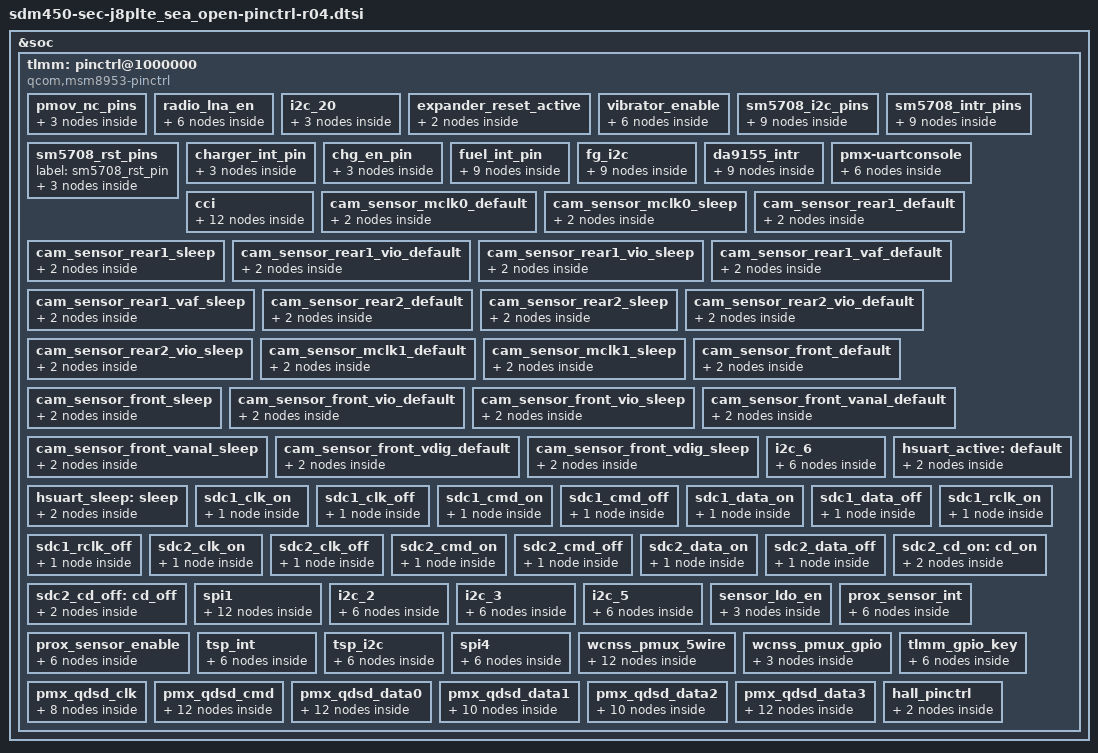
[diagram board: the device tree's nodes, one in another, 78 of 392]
/*
 * Copyright (c) 2015-2016, The Linux Foundation. All rights reserved.
 *
 * This program is free software; you can redistribute it and/or modify
 * it under the terms of the GNU General Public License version 2 and
 * only version 2 as published by the Free Software Foundation.
 *
 * This program is distributed in the hope that it will be useful,
 * but WITHOUT ANY WARRANTY; without even the implied warranty of
 * MERCHANTABILITY or FITNESS FOR A PARTICULAR PURPOSE.  See the
 * GNU General Public License for more details.
 */

#include "sdm450-sec-j8plte_audio-pinctrl.dtsi"

&soc {
	tlmm: pinctrl@1000000 {
		compatible = "qcom,msm8953-pinctrl";
		reg = <0x1000000 0x300000>;
		interrupts = <0 208 0>;
		gpio-controller;
		#gpio-cells = <2>;
		interrupt-controller;
		#interrupt-cells = <2>;

		pmov_nc_pins {
			label = "pmov_nc_pins";
			qcom,num-grp-pins = <1>;
			qcom,pin-func = <0>;
			nc_gpio_default: default {
				mux {
					pins = "gpio126";
					function ="gpio";
				};
				config {
					pins = "gpio126";
					drive-strength = <2>; /* 2mA */
					bias-pull-down;
					input-enable;
				};
			};
		};

		radio_lna_en {
				lna_en_default: lna_en_default {
					mux {
						pins = "gpio134";
						function = "gpio";
					};

					config {
						pins = "gpio134";
						drive-strength = <2>;
						bias-disable;
					};
				};
				lna_en_sleep: lna_en_sleep {
					mux {
						pins = "gpio134";
						function = "gpio";
					};

					config {
						pins = "gpio134";
						drive-strength = <2>;
						bias-disable;
					};
				};
		};

		i2c_20 {
			i2c_20_active: i2c_20_active {
				mux {
					pins = "gpio20", "gpio21";
					function = "gpio";
				};
				config {
					pins = "gpio20", "gpio21";
					drive-strength = <2>;
					bias-disable;
				};
			};
		};

		expander_reset_active: expander_reset_active {
			mux {
				pins = "gpio33";
				function = "gpio";
			};
			config {
				pins = "gpio33";
				drive-strength = <2>;   /* 16 mA */
				bias-disable;
				output-high;
			};
		};

		vibrator_enable{
			vibrator_enable_active: vibrator_enable_active {
				mux {
					pins = "gpio132";
					function = "gpio";
				};

				config {
					pins = "gpio132";
					drive-strength = <2>;
					output-high;
					bias-pull-down;
				};
			};

			vibrator_enable_suspend: vibrator_enable_suspend {
				mux {
					pins = "gpio132";
					function = "gpio";
				};

				config {
					pins = "gpio132";
					drive-strength = <2>;
					bias-disable;
					output-low;
				};
			};
		};

	/* MUIC - SM5708 */
		sm5708_i2c_pins {
			qcom,num-grp-pins = <2>;
			qcom,pin-func = <0>;
			label = "sm5708_gpio";
			sm5708_i2c_default: default {
				mux {
					pins = "gpio98", "gpio99";
					function = "gpio";
				};
				config {
					pins = "gpio98", "gpio99";
					drive-strength = <2>;
					bias-disable;
				};
			};
			sm5708_i2c_active: active {
				mux {
					pins = "gpio98", "gpio99";
					function = "gpio";
				};
				config {
					pins = "gpio98", "gpio99";
					drive-strength = <2>;
					bias-disable;
				};

			};
			sm5708_i2c_suspend: suspend {
				mux {
					pins = "gpio98", "gpio99";
					function = "gpio";
				};
				config {
					pins = "gpio98", "gpio99";
					drive-strength = <2>;
					bias-disable;
				};
			};
		};

		sm5708_intr_pins {
			qcom,pin-func = <0>;
			label = "sm5708_gpio_int";
			sm5708_interrupt_default: default {
				mux {
					pins = "gpio63";
					function = "gpio";
				};
				config {
					pins = "gpio63";
					drive-strength = <2>;
					bias-disable;
				};
			};
			sm5708_interrupt_active: active {
				mux {
					pins = "gpio63";
					function = "gpio";
				};
				config {
					pins = "gpio63";
					drive-strength = <2>;
					bias-disable;
				};
			};
			sm5708_interrupt_suspend: suspend {
				mux {
					pins = "gpio63";
					function = "gpio";
				};
				config {
					pins = "gpio63";
					drive-strength = <2>;
					bias-disable;
				};
			};
		};

		sm5708_rst_pins {
			label = "sm5708_rst_pin";
			sm5708_rst_default: default {
				mux {
					pins = "gpio61";
					function = "gpio";
				};
				config {
					pins = "gpio61";
					drive-strength = <2>;
					bias-disable;
					input-enable;
				};
			};
		};

		charger_int_pin {
			qcom,num-grp-pins = <1>;
			qcom,pin-func = <0>;
			label = "charger_int_gpio";
			charger_int_active: charger_int_active {
				mux {
					pins = "gpio60";
					function = "gpio";
				};
				config {
					pins = "gpio60";
					drive-strength = <2>;
					bias-disable;         /* No PULL */
				};
			};
		};

		chg_en_pin {
			pins = "gpio34";
			qcom,num-grp-pins = <1>;	
			qcom,pin-func = <0>;
			label = "chg_en_gpio";
			chg_en_default: chg_en_default {
				mux {
					pins = "gpio34";
					function = "gpio";
				};
				config {
					pins = "gpio34";
					drive-strength = <2>;
					bias-pull-down;
					output-high;
				};
			};
		};

		fuel_int_pin {
			qcom,num-grp-pins = <1>;
			qcom,pin-func = <0>;
			label = "fuel_int_gpio";

			fuel_int_default: fuel_int_default {
				mux {
					pins = "gpio62";
					function = "gpio";
				};
				config {
					pins = "gpio62";
					drive-strength = <2>;
					bias-disable;
				};
			};
			fuel_int_active: fuel_int_active {
				mux {
					pins = "gpio62";
					function = "gpio";
				};
				config {
					pins = "gpio62";
					drive-strength = <2>;
					bias-disable;
				};
			};
			fuel_int_suspend: fuel_int_suspend {
				mux {
					pins = "gpio62";
					function = "gpio";
				};
				config {
					pins = "gpio62";
					drive-strength = <2>;
					bias-disable;
				};
			};			
		};

		fg_i2c {
			qcom,num-grp-pins = <2>;
			qcom,pin-func = <0>;
			label = "sm5708_fg_gpio";
			
			fg_i2c_default: fg_i2c_default {
				mux {
					pins = "gpio38", "gpio39";
					function = "gpio";
				};
				config {
					pins = "gpio38", "gpio39";
					drive-strength = <2>;
					bias-disable; /* No PULL */
				};
			};
			fg_i2c_active: fg_i2c_active {
				mux {
					pins = "gpio38", "gpio39";
					function = "gpio";
				};
				config {
					pins = "gpio38", "gpio39";
					drive-strength = <2>;
					bias-disable; /* No PULL */
				};
			};
			fg_i2c_suspend: fg_i2c_suspend {
				mux {
					pins = "gpio38", "gpio39";
					function = "gpio";
				};
				config {
					pins = "gpio38", "gpio39";
					drive-strength = <2>;
					bias-disable; /* No PULL */
				};
			};
		};

		da9155_intr {
			qcom,pin-func = <0>;
			label = "da9155_intr";
			da9155_intr_default: default {
				mux {
					pins = "gpio9";
					function = "gpio";
				};
				config {
					pins = "gpio9";
					drive-strength = <2>;
					bias-disable;
				};
			};
			da9155_intr_active: active {
				mux {
					pins = "gpio9";
					function = "gpio";
				};
				config {
					pins = "gpio9";
					drive-strength = <2>;
					bias-disable;
				};
			};
			da9155_intr_suspend: suspend {
				mux {
					pins = "gpio9";
					function = "gpio";
				};
				config {
					pins = "gpio9";
					drive-strength = <2>;
					bias-disable;
				};
			};
		};

		pmx-uartconsole {
			uart_console_active: uart_console_active {
				mux {
					pins = "gpio4", "gpio5";
					function = "blsp_uart2";
				};

				config {
					pins = "gpio4", "gpio5";
					drive-strength = <2>;
					bias-pull-down;
				};
			};

			uart_console_sleep: uart_console_sleep {
				mux {
					pins = "gpio4", "gpio5";
					function = "blsp_uart2";
				};

				config {
					pins = "gpio4", "gpio5";
					drive-strength = <2>;
					bias-pull-down;
				};
			};

		};
		cci {
			cci0_active: cci0_active {
				/* cci0 active state */
				mux {
					/* CLK, DATA */
					pins = "gpio29", "gpio30";
					function = "cci_i2c";
				};

				config {
					pins = "gpio29", "gpio30";
					drive-strength = <2>; /* 2 MA */
					bias-disable; /* No PULL */
				};
			};

			cci0_suspend: cci0_suspend {
				/* cci0 suspended state */
				mux {
					/* CLK, DATA */
					pins = "gpio29", "gpio30";
					function = "gpio";
				};

				config {
					pins = "gpio29", "gpio30";
					drive-strength = <2>; /* 2 MA */
					bias-disable; /* No PULL */
				};
			};

			cci1_active: cci1_active {
				/* cci1 active state */
				mux {
					/* CLK, DATA */
					pins = "gpio31", "gpio32";
					function = "cci_i2c";
				};

				config {
					pins = "gpio31", "gpio32";
					drive-strength = <2>; /* 2 MA */
					bias-disable; /* No PULL */
				};
			};

			cci1_suspend: cci1_suspend {
				/* cci1 suspended state */
				mux {
					/* CLK, DATA */
					pins = "gpio31", "gpio32";
					function = "gpio";
				};

				config {
					pins = "gpio31", "gpio32";
					drive-strength = <2>; /* 2 MA */
					bias-disable; /* No PULL */
				};
			};
		};

		/*sensors */
		cam_sensor_mclk0_default: cam_sensor_mclk0_default {
			/* MCLK0 */
			mux {
				/* CLK, DATA */
				pins = "gpio26";
				function = "cam_mclk";
			};

			config {
				pins = "gpio26";
				bias-disable; /* No PULL */
				drive-strength = <4>; /* 4 MA */
			};
		};

		cam_sensor_mclk0_sleep: cam_sensor_mclk0_sleep {
			/* MCLK0 */
			mux {
				/* CLK, DATA */
				pins = "gpio26";
				function = "gpio";
			};

			config {
				pins = "gpio26";
				bias-pull-down; /* PULL DOWN */
				drive-strength = <4>; /* 4 MA */
				output-low;
			};
		};

		cam_sensor_rear1_default: cam_sensor_rear1_default {
			/* REAR MAIN RESET */
			mux {
				pins = "gpio40";
				function = "gpio";
			};

			config {
				pins = "gpio40";
				bias-pull-down; /* PULL DOWN */
				drive-strength = <2>; /* 2 MA */
				output-low;
			};
		};

		cam_sensor_rear1_sleep: cam_sensor_rear1_sleep {
			/* REAR MAIN RESET */
			mux {
				pins = "gpio40";
				function = "gpio";
			};

			config {
				pins = "gpio40";
				bias-pull-down; /* PULL DOWN */
				drive-strength = <2>; /* 2 MA */
			};
		};

		cam_sensor_rear1_vio_default: cam_sensor_rear1_vio_default {
			/* REAR MAIN VIO */
			mux {
				pins = "gpio92";
				function = "gpio";
			};

			config {
				pins = "gpio92";
				bias-pull-down; /* PULL DOWN */
				drive-strength = <2>; /* 2 MA */
				output-low;
			};
		};

		cam_sensor_rear1_vio_sleep: cam_sensor_rear1_vio_sleep {
			/* REAR MAIN VDIO */
			mux {
				pins = "gpio92";
				function = "gpio";
			};

			config {
				pins = "gpio92";
				bias-pull-down; /* PULL DOWN */
				drive-strength = <2>; /* 2 MA */
				output-low;
			};
		};

		cam_sensor_rear1_vaf_default: cam_sensor_rear1_vaf_default {
			/* REAR MAIN VAF */
			mux {
				pins = "gpio89";
				function = "gpio";
			};

			config {
				pins = "gpio89";
				bias-pull-down; /* PULL DOWN */
				drive-strength = <2>; /* 2 MA */
				output-low;
			};
		};

		cam_sensor_rear1_vaf_sleep: cam_sensor_rear1_vaf_sleep {
			/* REAR MAIN VAF */
			mux {
				pins = "gpio89";
				function = "gpio";
			};

			config {
				pins = "gpio89";
				bias-pull-down; /* PULL DOWN */
				drive-strength = <2>; /* 2 MA */
				output-low;
			};
		};

		cam_sensor_rear2_default: cam_sensor_rear2_default {
			/* REAR SUB RESET */
			mux {
				pins = "gpio41";
				function = "gpio";
			};

			config {
				pins = "gpio41";
				bias-pull-down; /* PULL DOWN */
				drive-strength = <2>; /* 2 MA */
				output-low;
			};
		};

		cam_sensor_rear2_sleep: cam_sensor_rear2_sleep {
			/* REAR SUB RESET */
			mux {
				pins = "gpio41";
				function = "gpio";
			};

			config {
				pins = "gpio41";
				bias-pull-down; /* PULL DOWN */
				drive-strength = <2>; /* 2 MA */
			};
		};

		cam_sensor_rear2_vio_default: cam_sensor_rear2_vio_default {
			/* REAR SUB VIO */
			mux {
				pins = "gpio94";
				function = "gpio";
			};

			config {
				pins = "gpio94";
				bias-pull-down; /* PULL DOWN */
				drive-strength = <2>; /* 2 MA */
				output-low;
			};
		};

		cam_sensor_rear2_vio_sleep: cam_sensor_rear2_vio_sleep {
			/* REAR SUB VIO */
			mux {
				pins = "gpio94";
				function = "gpio";
			};

			config {
				pins = "gpio94";
				bias-pull-down; /* PULL DOWN */
				drive-strength = <2>; /* 2 MA */
				output-low;
			};
		};

		cam_sensor_mclk1_default: cam_sensor_mclk1_default {
			/* MCLK1 */
			mux {
				/* CLK, DATA */
				pins = "gpio27";
				function = "cam_mclk";
			};

			config {
				pins = "gpio27";
				bias-disable; /* No PULL */
				drive-strength = <4>; /* 4 MA */
			};
		};

		cam_sensor_mclk1_sleep: cam_sensor_mclk1_sleep {
			/* MCLK1 */
			mux {
				/* CLK, DATA */
				pins = "gpio27";
				function = "gpio";
			};

			config {
				pins = "gpio27";
				bias-pull-down; /* PULL DOWN */
				drive-strength = <4>; /* 4 MA */
				output-low;
			};
		};

		cam_sensor_front_default: cam_sensor_front_default {
			/* FRONT RESET*/
			mux {
				pins = "gpio129";
				function = "gpio";
			};

			config {
				pins = "gpio129";
				bias-pull-down; /* PULL DOWN */
				output-low;
				drive-strength = <2>; /* 2 MA */
			};
		};

		cam_sensor_front_sleep: cam_sensor_front_sleep {
			/* FRONT RESET */
			mux {
				pins = "gpio129";
				function = "gpio";
			};

			config {
				pins = "gpio129";
				bias-disable; /* No PULL */
				output-low;
				drive-strength = <2>; /* 2 MA */
			};
		};

		cam_sensor_front_vio_default: cam_sensor_front_vio_default {
			/* FRONT VIO */
			mux {
				pins = "gpio90";
				function = "gpio";
			};

			config {
				pins = "gpio90";
				bias-pull-down; /* PULL DOWN */
				drive-strength = <2>; /* 2 MA */
				output-low;
			};
		};

		cam_sensor_front_vio_sleep: cam_sensor_front_vio_sleep {
			/* FRONT VIO */
			mux {
				pins = "gpio90";
				function = "gpio";
			};

			config {
				pins = "gpio90";
				bias-pull-down; /* PULL DOWN */
				drive-strength = <2>; /* 2 MA */
				output-low;
			};
		};

		cam_sensor_front_vanal_default: cam_sensor_front_vanal_default {
			/* FRONT VANAL */
			mux {
				pins = "gpio91";
				function = "gpio";
			};

			config {
				pins = "gpio91";
				bias-pull-down; /* PULL DOWN */
				drive-strength = <2>; /* 2 MA */
				output-low;
			};
		};

		cam_sensor_front_vanal_sleep: cam_sensor_front_vanal_sleep {
			/* FRONT VANAL */
			mux {
				pins = "gpio91";
				function = "gpio";
			};

			config {
				pins = "gpio91";
				bias-pull-down; /* PULL DOWN */
				drive-strength = <2>; /* 2 MA */
				output-low;
			};
		};

		cam_sensor_front_vdig_default: cam_sensor_front_vdig_default {
			/* FRONT VDIG */
			mux {
				pins = "gpio140";
				function = "gpio";
			};

			config {
				pins = "gpio140";
				bias-pull-down; /* PULL DOWN */
				drive-strength = <2>; /* 2 MA */
				output-low;
			};
		};

		cam_sensor_front_vdig_sleep: cam_sensor_front_vdig_sleep {
			/* FRONT VDIG */
			mux {
				pins = "gpio140";
				function = "gpio";
			};

			config {
				pins = "gpio140";
				bias-pull-down; /* PULL DOWN */
				drive-strength = <2>; /* 2 MA */
				output-low;
			};
		};
/*
		pmx_adv7533_int: pmx_adv7533_int {
			adv7533_int_active: adv7533_int_active {
				mux {
					pins = "gpio90";
					function = "gpio";
				};

				config {
					pins = "gpio90";
					drive-strength = <16>;
					bias-disable;
				};
			};

			adv7533_int_suspend: adv7533_int_suspend {
				mux {
					pins = "gpio90";
					function = "gpio";
				};

				config {
					pins = "gpio90";
					drive-strength = <16>;
					bias-disable;
				};
			};

		};
*/
		i2c_6 {
			i2c_6_active: i2c_6_active {
				/* active state */
				mux {
					pins = "gpio22", "gpio23";
					function = "blsp_i2c6";
				};
				config {
					pins = "gpio22", "gpio23";
					drive-strength = <2>;
					bias-disable;
				};
			};

			i2c_6_sleep: i2c_6_sleep {
				/* suspended state */
				mux {
					pins = "gpio22", "gpio23";
					function = "blsp_i2c6";
				};

				config {
					pins = "gpio22", "gpio23";
					drive-strength = <2>;
					bias-disable;
				};
			};
		};

		hsuart_active: default {
			mux {
				pins = "gpio12", "gpio13", "gpio14", "gpio15";
				function = "blsp_uart4";
			};

			config {
				pins = "gpio12", "gpio13", "gpio14", "gpio15";
				drive-strength = <16>;
				bias-disable;
			};
		};

		hsuart_sleep: sleep {
			mux {
				pins = "gpio12", "gpio13", "gpio14", "gpio15";
				function = "gpio";
			};

			config {
				pins = "gpio12", "gpio13", "gpio14", "gpio15";
				drive-strength = <2>;
				bias-disable;
			};
		};

		/* SDC pin type */
		sdc1_clk_on: sdc1_clk_on {
			config {
				pins = "sdc1_clk";
				bias-disable;		/* NO pull */
				drive-strength = <16>;	/* 16 MA */
			};
		};

		sdc1_clk_off: sdc1_clk_off {
			config {
				pins = "sdc1_clk";
				bias-disable;		/* NO pull */
				drive-strength = <2>;	/* 2 MA */
			};
		};

		sdc1_cmd_on: sdc1_cmd_on {
			config {
				pins = "sdc1_cmd";
				bias-disable;		/* NO pull */
				drive-strength = <10>;	/* 10 MA */
			};
		};

		sdc1_cmd_off: sdc1_cmd_off {
			config {
				pins = "sdc1_cmd";
				num-grp-pins = <1>;
				bias-disable;		/* NO pull */
				drive-strength = <2>;	/* 2 MA */
			};
		};

		sdc1_data_on: sdc1_data_on {
			config {
				pins = "sdc1_data";
				bias-pull-up;		/* pull up */
				drive-strength = <10>;	/* 10 MA */
			};
		};

		sdc1_data_off: sdc1_data_off {
			config {
				pins = "sdc1_data";
				bias-pull-up;		/* pull up */
				drive-strength = <2>;	/* 2 MA */
			};
		};

		sdc1_rclk_on: sdc1_rclk_on {
			config {
				pins = "sdc1_rclk";
				bias-pull-down; /* pull down */
			};
		};

		sdc1_rclk_off: sdc1_rclk_off {
			config {
				pins = "sdc1_rclk";
				bias-pull-down; /* pull down */
			};
		};

		sdc2_clk_on: sdc2_clk_on {
			config {
				pins = "sdc2_clk";
				drive-strength = <16>; /* 16 MA */
				bias-disable; /* NO pull */
			};
		};

		sdc2_clk_off: sdc2_clk_off {
			config {
				pins = "sdc2_clk";
				bias-disable; /* NO pull */
				drive-strength = <2>; /* 2 MA */
			};
		};

		sdc2_cmd_on: sdc2_cmd_on {
			config {
				pins = "sdc2_cmd";
				bias-pull-up; /* pull up */
				drive-strength = <8>; /* 8 MA */
			};
		};

		sdc2_cmd_off: sdc2_cmd_off {
			config {
				pins = "sdc2_cmd";
				bias-pull-up; /* pull up */
				drive-strength = <2>; /* 2 MA */
			};
		};

		sdc2_data_on: sdc2_data_on {
			config {
				pins = "sdc2_data";
				bias-pull-up; /* pull up */
				drive-strength = <8>; /* 8 MA */
			};
		};

		sdc2_data_off: sdc2_data_off {
			config {
				pins = "sdc2_data";
				bias-pull-up; /* pull up */
				drive-strength = <2>; /* 2 MA */
			};
		};

		sdc2_cd_on: cd_on {
			mux {
				pins = "gpio133";
				function = "gpio";
			};

			config {
				pins = "gpio133";
				drive-strength = <2>;
				bias-disable;
			};
		};

		sdc2_cd_off: cd_off {
			mux {
				pins = "gpio133";
				function = "gpio";
			};

			config {
				pins = "gpio133";
				drive-strength = <2>;
				bias-disable;
			};
		};

		spi1 {
			spi1_default: spi1_default {
				/* active state */
				mux {
					/* MOSI, MISO, CLK */
					pins = "gpio0", "gpio1", "gpio3";
					function = "blsp_spi1";
				};

				config {
					pins = "gpio0", "gpio1", "gpio2";
					drive-strength = <12>; /* 12 MA */
					bias-disable = <0>; /* No PULL */
				};
			};

			spi1_sleep: spi1_sleep {
				/* suspended state */
				mux {
					/* MOSI, MISO, CLK */
					pins = "gpio0", "gpio1", "gpio3";
					function = "gpio";
				};

				config {
					pins = "gpio0", "gpio1", "gpio3";
					drive-strength = <2>; /* 2 MA */
					bias-pull-down; /* PULL Down */
				};
			};

			spi1_cs0_active: cs0_active {
				/* CS */
				mux {
					pins = "gpio2";
					function = "blsp_spi1";
				};

				config {
					pins = "gpio2";
					drive-strength = <2>;
					bias-disable = <0>;
				};
			};

			spi1_cs0_sleep: cs0_sleep {
				/* CS */
				mux {
					pins = "gpio2";
					function = "gpio";
				};

				config {
					pins = "gpio2";
					drive-strength = <2>;
					bias-disable = <0>;
				};
			};
		};

		i2c_2 {
			i2c_2_active: i2c_2_active {
				/* active state */
				mux {
					pins = "gpio6", "gpio7";
					function = "blsp_i2c2";
				};

				config {
					pins = "gpio6", "gpio7";
					drive-strength = <2>;
					bias-disable;
				};
			};

			i2c_2_sleep: i2c_2_sleep {
				/* suspended state */
				mux {
					pins = "gpio6", "gpio7";
					function = "blsp_i2c2";
				};

				config {
					pins = "gpio6", "gpio7";
					drive-strength = <2>;
					bias-disable;
				};
			};
		};

		i2c_3 {
			i2c_3_active: i2c_3_active {
				/* active state */
				mux {
					pins = "gpio10", "gpio11";
					function = "blsp_i2c3";
				};

				config {
					pins = "gpio10", "gpio11";
					drive-strength = <2>;
					bias-disable;
				};
			};

			i2c_3_sleep: i2c_3_sleep {
				/* suspended state */
				mux {
					pins = "gpio10", "gpio11";
					function = "gpio";
				};

				config {
					pins = "gpio10", "gpio11";
					drive-strength = <2>;
					bias-disable;
				};
			};
		};

		i2c_5 {
			i2c_5_active: i2c_5_active {
				/* active state */
				mux {
					pins = "gpio18", "gpio19";
					function = "blsp_i2c5";
				};

				config {
					pins = "gpio18", "gpio19";
					drive-strength = <2>;
					bias-disable;
				};
			};

			i2c_5_sleep: i2c_5_sleep {
				/* suspended state */
				mux {
					pins = "gpio18", "gpio19";
					function = "blsp_i2c5";
				};

				config {
					pins = "gpio18", "gpio19";
					drive-strength = <2>;
					bias-disable;
				};
			};
		};

		sensor_ldo_en {
			pins = "gpio66";
			qcom,pin-func = <0>;
			qcom,num-grp-pins = <1>;
			label = "sensor_ldo_en";
			sensor_ldo_en_default: sensor_ldo_en_default {
				mux {
					pins = "gpio66";
					function = "gpio";
				};
				config {
					pins = "gpio66";
					drive-strength = <2>;
					bias-disable;
					output-high;
				};
			};
		};

		/* add pingrp for proximity sensors  */
		prox_sensor_int {
			pins = "gpio43";
			qcom,pin-func = <0>;
			qcom,num-grp-pins = <1>;
			label = "prox_sensor_int";
			prox_sensor_int_active: prox_sensor_int_active {
				mux {
					pins = "gpio43";
					function = "gpio";
				};
				config {
					pins = "gpio43";
					drive-strength = <2>;
					bias-disable;
				};
			};
			prox_sensor_int_suspend: prox_sensor_int_suspend {
				mux {
					pins = "gpio43";
					function = "gpio";
				};
				config {
					pins = "gpio43";
					drive-strength = <2>;
					bias-disable;
				};
			};
		};

		prox_sensor_enable {
			pins = "gpio96";
			qcom,pin-func = <0>;
			qcom,num-grp-pins = <1>;
			label = "prox_sensor_enable";
			prox_sensor_enable_active: prox_sensor_enable_active {
				mux {
					pins = "gpio96";
					function = "gpio";
				};
				config {
					pins = "gpio96";
					drive-strength = <2>;
					bias-pull-down;
				};
			};
			prox_sensor_enable_suspend: prox_sensor_enable_suspend {
				mux {
					pins = "gpio96";
					function = "gpio";
				};
				config {
					pins = "gpio96";
					drive-strength = <2>;
					bias-pull-down;
				};
			};
		};

		tsp_int {
			/*qcom,pins = <&gp 59>;*/ /* INTERRUPT */
			pins = "gpio59";
			qcom,num-grp-pins = <1>;
			qcom,pin-func = <0>;
			label = "tsp_int";
			tsp_int_active: tsp_int_active {
				mux {
					pins = "gpio59";
					function = "gpio";
				};
				config {
					pins = "gpio59";
					drive-strength = <2>;
					bias-disable;
				};
			};
			tsp_int_suspend: tsp_int_suspend {
				mux {
					pins = "gpio59";
					function = "gpio";
				};
				config {
					pins = "gpio59";
					drive-strength = <2>;
					bias-disable;
				};
			};
		};

		tsp_i2c {
			/*qcom,pins = <&gp 16>, <&gp 17>;*/ /* SDA, SCL */
			pins = "gpio16", "gpio17";
			qcom,num-grp-pins = <2>;
			qcom,pin-func = <0>;
			label = "tsp_i2c";
			tsp_i2c_active: tsp_i2c_active {
				mux {
					pins = "gpio16", "gpio17";
					function = "gpio";
				};
				config {
					pins = "gpio16", "gpio17";
					drive-strength = <2>;
					bias-disable;
				};
			};
			tsp_i2c_suspend: tsp_i2c_suspend {
				mux {
					pins = "gpio16", "gpio17";
					function = "gpio";
				};
				config {
					pins = "gpio16", "gpio17";
					drive-strength = <2>;
					bias-pull-down;
				};
			};
		};

		spi4 {
			spi_4_active: spi_4_active {
				mux {
					pins = "gpio12", "gpio13", "gpio14", "gpio15";
					function = "blsp_spi4";
				};

				config {
					pins = "gpio12", "gpio13", "gpio14", "gpio15";
					drive-strength = <2>;
					bias-pull-up;
				};
			};

			spi_4_sleep: spi_4_sleep {
				mux {
					pins = "gpio12", "gpio13", "gpio14", "gpio15";
					function = "blsp_spi4";
				};

				config {
					pins = "gpio12", "gpio13", "gpio14", "gpio15";
					drive-strength = <2>;
					bias-pull-down;
				};
			};
		};

		wcnss_pmux_5wire {
			/* Active configuration of bus pins */
			wcnss_default: wcnss_default {
				wcss_wlan2 {
					pins = "gpio76";
					function = "wcss_wlan2";
				};
				wcss_wlan1 {
					pins = "gpio77";
					function = "wcss_wlan1";
				};
				wcss_wlan0 {
					pins = "gpio78";
					function = "wcss_wlan0";
				};
				wcss_wlan {
					pins = "gpio79", "gpio80";
					function = "wcss_wlan";
				};

				config {
					pins = "gpio76", "gpio77",
						"gpio78", "gpio79",
						"gpio80";
					drive-strength = <6>; /* 6 MA */
					bias-pull-up; /* PULL UP */
				};
			};

			wcnss_sleep: wcnss_sleep {
				wcss_wlan2 {
					pins = "gpio76";
					function = "wcss_wlan2";
				};
				wcss_wlan1 {
					pins = "gpio77";
					function = "wcss_wlan1";
				};
				wcss_wlan0 {
					pins = "gpio78";
					function = "wcss_wlan0";
				};
				wcss_wlan {
					pins = "gpio79", "gpio80";
					function = "wcss_wlan";
				};

				config {
					pins = "gpio76", "gpio77",
						"gpio78", "gpio79",
						"gpio80";
					drive-strength = <2>; /* 2 MA */
					bias-pull-down; /* PULL Down */
				};
			};
		};

		wcnss_pmux_gpio: wcnss_pmux_gpio {
			wcnss_gpio_default: wcnss_gpio_default {
				/* Active configuration of bus pins */
				mux {
					/* Uses general purpose pins */
					pins = "gpio76", "gpio77",
					"gpio78", "gpio79",
					"gpio80";
					function = "gpio";
				};

				config {
					pins = "gpio76", "gpio77",
						"gpio78", "gpio79",
						"gpio80";
					drive-strength = <6>; /* 6 MA */
					bias-pull-up; /* PULL UP */
				};
			};
		};

		tlmm_gpio_key {
			gpio_key_active: gpio_key_active {
				mux {
					pins = "gpio85";
					function = "gpio";
				};

				config {
					pins = "gpio85";
					drive-strength = <2>;
					bias-pull-up;
				};
			};

			gpio_key_suspend: gpio_key_suspend {
				mux {
					pins = "gpio85";
					function = "gpio";
				};

				config {
					pins = "gpio85";
					drive-strength = <2>;
					bias-pull-up;
				};
			};
		};
		pmx_qdsd_clk {
			qdsd_clk_sdcard: clk_sdcard {
				config {
					pins = "qdsd_clk";
					bias-disable;/* NO pull */
					drive-strength = <16>; /* 16 MA */
				};
			};
			qdsd_clk_trace: clk_trace {
				config {
					pins = "qdsd_clk";
					bias-pull-down; /* pull down */
					drive-strength = <2>; /* 2 MA */
				};
			};
			qdsd_clk_swdtrc: clk_swdtrc {
				config {
					pins = "qdsd_clk";
					bias-pull-down; /* pull down */
					drive-strength = <2>; /* 2 MA */
				};
			};
			qdsd_clk_spmi: clk_spmi {
				config {
					pins = "qdsd_clk";
					bias-pull-down; /* pull down */
					drive-strength = <2>; /* 2 MA */
				};
			};
		};

		pmx_qdsd_cmd {
			qdsd_cmd_sdcard: cmd_sdcard {
				config {
					pins = "qdsd_cmd";
					bias-pull-down; /* pull down */
					drive-strength = <8>; /* 8 MA */
				};
			};
			qdsd_cmd_trace: cmd_trace {
				config {
					pins = "qdsd_cmd";
					bias-pull-down; /* pull down */
					drive-strength = <2>; /* 2 MA */
				};
			};
			qdsd_cmd_swduart: cmd_uart {
				config {
					pins = "qdsd_cmd";
					bias-pull-up; /* pull up */
					drive-strength = <2>; /* 2 MA */
				};
			};
			qdsd_cmd_swdtrc: cmd_swdtrc {
				config {
					pins = "qdsd_cmd";
					bias-pull-up; /* pull up */
					drive-strength = <2>; /* 2 MA */
				};
			};
			qdsd_cmd_jtag: cmd_jtag {
				config {
					pins = "qdsd_cmd";
					bias-disable; /* NO pull */
					drive-strength = <8>; /* 8 MA */
				};
			};
			qdsd_cmd_spmi: cmd_spmi {
				config {
					pins = "qdsd_cmd";
					bias-pull-down; /* pull down */
					drive-strength = <10>; /* 10 MA */
				};
			};
		};

		pmx_qdsd_data0 {
			qdsd_data0_sdcard: data0_sdcard {
				config {
					pins = "qdsd_data0";
					bias-pull-down; /* pull down */
					drive-strength = <8>; /* 8 MA */
				};
			};
			qdsd_data0_trace: data0_trace {
				config {
					pins = "qdsd_data0";
					bias-pull-down; /* pull down */
					drive-strength = <8>; /* 8 MA */
				};
			};
			qdsd_data0_swduart: data0_uart {
				config {
					pins = "qdsd_data0";
					bias-pull-down; /* pull down */
					drive-strength = <2>; /* 2 MA */
				};
			};
			qdsd_data0_swdtrc: data0_swdtrc {
				config {
					pins = "qdsd_data0";
					bias-pull-down; /* pull down */
					drive-strength = <2>; /* 2 MA */
				};
			};
			qdsd_data0_jtag: data0_jtag {
				config {
					pins = "qdsd_data0";
					bias-pull-up; /* pull up */
					drive-strength = <2>; /* 2 MA */
				};
			};
			qdsd_data0_spmi: data0_spmi {
				config {
					pins = "qdsd_data0";
					bias-pull-down; /* pull down */
					drive-strength = <2>; /* 2 MA */
				};
			};
		};

		pmx_qdsd_data1 {
			qdsd_data1_sdcard: data1_sdcard {
				config {
					pins = "qdsd_data1";
					bias-pull-down; /* pull down */
					drive-strength = <8>; /* 8 MA */
				};
			};
			qdsd_data1_trace: data1_trace {
				config {
					pins = "qdsd_data1";
					bias-pull-down; /* pull down */
					drive-strength = <8>; /* 8 MA */
				};
			};
			qdsd_data1_swduart: data1_uart {
				config {
					pins = "qdsd_data1";
					bias-pull-down; /* pull down */
					drive-strength = <2>; /* 2 MA */
				};
			};
			qdsd_data1_swdtrc: data1_swdtrc {
				config {
					pins = "qdsd_data1";
					bias-pull-down; /* pull down */
					drive-strength = <2>; /* 2 MA */
				};
			};
			qdsd_data1_jtag: data1_jtag {
				config {
					pins = "qdsd_data1";
					bias-pull-down; /* pull down */
					drive-strength = <2>; /* 2 MA */
				};
			};
		};

		pmx_qdsd_data2 {
			qdsd_data2_sdcard: data2_sdcard {
				config {
					pins = "qdsd_data2";
					bias-pull-down; /* pull down */
					drive-strength = <8>; /* 8 MA */
				};
			};
			qdsd_data2_trace: data2_trace {
				config {
					pins = "qdsd_data2";
					bias-pull-down; /* pull down */
					drive-strength = <8>; /* 8 MA */
				};
			};
			qdsd_data2_swduart: data2_uart {
				config {
					pins = "qdsd_data2";
					bias-pull-down; /* pull down */
					drive-strength = <2>; /* 2 MA */
				};
			};
			qdsd_data2_swdtrc: data2_swdtrc {
				config {
					pins = "qdsd_data2";
					bias-pull-down; /* pull down */
					drive-strength = <2>; /* 2 MA */
				};
			};
			qdsd_data2_jtag: data2_jtag {
				config {
					pins = "qdsd_data2";
					bias-pull-up; /* pull up */
					drive-strength = <8>; /* 8 MA */
				};
			};
		};

		pmx_qdsd_data3 {
			qdsd_data3_sdcard: data3_sdcard {
				config {
					pins = "qdsd_data3";
					bias-pull-down; /* pull down */
					drive-strength = <8>; /* 8 MA */
				};
			};
			qdsd_data3_trace: data3_trace {
				config {
					pins = "qdsd_data3";
					bias-pull-down; /* pull down */
					drive-strength = <8>; /* 8 MA */
				};
			};
			qdsd_data3_swduart: data3_uart {
				config {
					pins = "qdsd_data3";
					bias-pull-up; /* pull up */
					drive-strength = <2>; /* 2 MA */
				};
			};
			qdsd_data3_swdtrc: data3_swdtrc {
				config {
					pins = "qdsd_data3";
					bias-pull-up; /* pull up */
					drive-strength = <2>; /* 2 MA */
				};
			};
			qdsd_data3_jtag: data3_jtag {
				config {
					pins = "qdsd_data3";
					bias-pull-up; /* pull up */
					drive-strength = <2>; /* 2 MA */
				};
			};
			qdsd_data3_spmi: data3_spmi {
				config {
					pins = "qdsd_data3";
					bias-pull-down; /* pull down */
					drive-strength = <8>; /* 8 MA */
				};
			};
		};

                hall_pinctrl: hall_pinctrl {
                        mux {
                                pins = "gpio44";
                                function = "gpio";
                        };
                        config {
                                pins = "gpio44";
                                drive-strength = <2>;   /* 16 mA */
				bias-disable;
                                input-enable;
                        };
                };
	};
};
